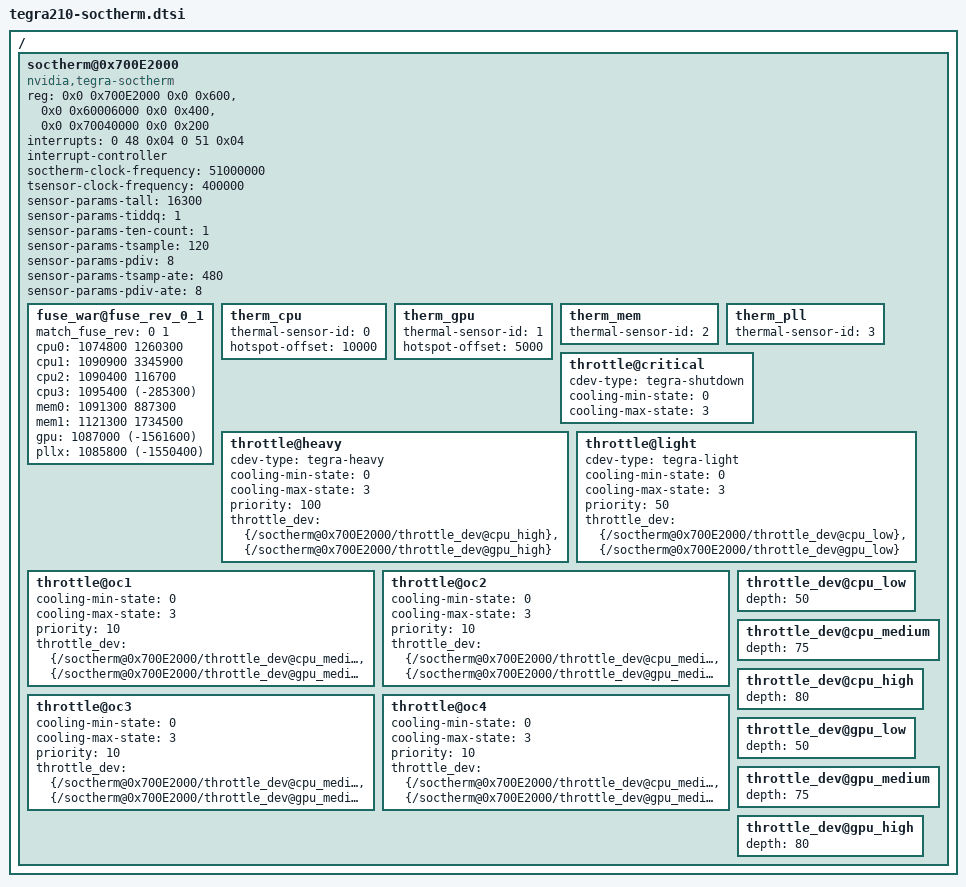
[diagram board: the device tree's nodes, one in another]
/*
 * arch/arm/boot/dts/tegra210-platforms/tegra210-soctherm.dtsi
 *
 * Copyright (c) 2014, NVIDIA CORPORATION. All rights reserved.
 *
 * This program is free software; you can redistribute it and/or modify it
 * under the terms and conditions of the GNU General Public License,
 * version 2, as published by the Free Software Foundation.
 *
 * This program is distributed in the hope it will be useful, but WITHOUT
 * ANY WARRANTY; without even the implied warranty of MERCHANTABILITY or
 * FITNESS FOR A PARTICULAR PURPOSE.  See the GNU General Public License for
 * more details.
 *
 * You should have received a copy of the GNU General Public License
 * along with this program.  If not, see <http://www.gnu.org/licenses/>.
 */

/ {
	soctherm@0x700E2000 {
		compatible = "nvidia,tegra-soctherm";
		reg =	<0x0 0x700E2000 0x0 0x600>, /* 0: SOC_THERM reg_base */
			<0x0 0x60006000 0x0 0x400>, /* 1: CAR reg_base */
			<0x0 0x70040000 0x0 0x200>; /* 2: CCROC reg_base */
		interrupts = <0 48 0x04
			      0 51 0x04>;
		#thermal-sensor-cells = <1>;
		status = "okay";
		interrupt-controller;
		#interrupt-cells = <2>;
		soctherm-clock-frequency = <51000000>;
		tsensor-clock-frequency  = <400000>;
		sensor-params-tall       = <16300>;
		sensor-params-tiddq      = <1>;
		sensor-params-ten-count  = <1>;
		sensor-params-tsample    = <120>;
		sensor-params-pdiv       = <8>;
		sensor-params-tsamp-ate  = <480>;
		sensor-params-pdiv-ate   = <8>;
		fuse_war@fuse_rev_0_1 {
			device_type = "fuse_war";
			match_fuse_rev = <0 1>;
			cpu0 = <1074800    1260300 >;
			cpu1 = <1090900    3345900 >;
			cpu2 = <1090400     116700 >;
			cpu3 = <1095400   (-285300)>;
			mem0 = <1091300     887300 >;
			mem1 = <1121300    1734500 >;
			gpu  = <1087000  (-1561600)>;
			pllx = <1085800  (-1550400)>;
		};
		/* thermctl - groups of sensors */
		therm_cpu {
			device_type = "thermctl";
			thermal-sensor-id = <0>;
			hotspot-offset = <10000>;
		};
		therm_gpu {
			device_type = "thermctl";
			thermal-sensor-id = <1>;
			hotspot-offset = <5000>;
		};
		therm_mem {
			device_type = "thermctl";
			thermal-sensor-id = <2>;
		};
		therm_pll {
			device_type = "thermctl";
			thermal-sensor-id = <3>;
		};

		/* throttlectl - hardware 'throttle' devices */
		throttle@critical {
			device_type = "throttlectl";
			cdev-type = "tegra-shutdown";
			cooling-min-state = <0>;
			cooling-max-state = <3>;
			#cooling-cells = <2>;
		};
		throttle@heavy {
			device_type = "throttlectl";
			cdev-type = "tegra-heavy";
			cooling-min-state = <0>;
			cooling-max-state = <3>;
			#cooling-cells = <2>;
			priority = <100>;
			throttle_dev = <&{/soctherm@0x700E2000/throttle_dev@cpu_high}
					&{/soctherm@0x700E2000/throttle_dev@gpu_high}>;
		};
		throttle@light {
			device_type = "throttlectl";
			cdev-type = "tegra-light";
			cooling-min-state = <0>;
			cooling-max-state = <3>;
			#cooling-cells = <2>;
			priority = <50>;
			throttle_dev = <&{/soctherm@0x700E2000/throttle_dev@cpu_low}
					&{/soctherm@0x700E2000/throttle_dev@gpu_low}>;
		};
		throttle@oc1 {
			device_type = "throttlectl";
			cooling-min-state = <0>;
			cooling-max-state = <3>;
			#cooling-cells = <2>;
			priority = <10>;
			throttle_dev = <&{/soctherm@0x700E2000/throttle_dev@cpu_medium}
					&{/soctherm@0x700E2000/throttle_dev@gpu_medium}>;
		};
		throttle@oc2 {
			device_type = "throttlectl";
			cooling-min-state = <0>;
			cooling-max-state = <3>;
			#cooling-cells = <2>;
			priority = <10>;
			throttle_dev = <&{/soctherm@0x700E2000/throttle_dev@cpu_medium}
					&{/soctherm@0x700E2000/throttle_dev@gpu_medium}>;
		};
		throttle@oc3 {
			device_type = "throttlectl";
			cooling-min-state = <0>;
			cooling-max-state = <3>;
			#cooling-cells = <2>;
			priority = <10>;
			throttle_dev = <&{/soctherm@0x700E2000/throttle_dev@cpu_medium}
					&{/soctherm@0x700E2000/throttle_dev@gpu_medium}>;
		};
		throttle@oc4 {
			device_type = "throttlectl";
			cooling-min-state = <0>;
			cooling-max-state = <3>;
			#cooling-cells = <2>;
			priority = <10>;
			throttle_dev = <&{/soctherm@0x700E2000/throttle_dev@cpu_medium}
					&{/soctherm@0x700E2000/throttle_dev@gpu_medium}>;
		};

		/* TODO - throttle_dev - pulse skip cfg and parse the phandles */
		throttle_dev@cpu_low {
			device_type = "throttle_dev";
			depth = <50>;
		};
		throttle_dev@cpu_medium {
			device_type = "throttle_dev";
			depth = <75>;
		};
		throttle_dev@cpu_high {
			device_type = "throttle_dev";
			depth = <80>;
		};
		throttle_dev@gpu_low {
			device_type = "throttle_dev";
			depth = <50>;
		};
		throttle_dev@gpu_medium {
			device_type = "throttle_dev";
			depth = <75>;
		};
		throttle_dev@gpu_high {
			device_type = "throttle_dev";
			depth = <80>;
		};
	};
};
